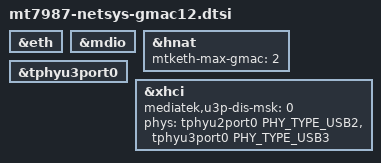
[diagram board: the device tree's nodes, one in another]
// SPDX-License-Identifier: (GPL-2.0 OR MIT)

#include "mt7987-netsys-gmac123.dtsi"

&eth {
	/delete-node/ mac@2;
};

&mdio {
	/delete-node/ phy@11;
};

&hnat {
	mtketh-max-gmac = <2>;
};

&tphyu3port0 {
	status = "okay";
};

&xhci {
	mediatek,u3p-dis-msk=<0>;

	phys = <&tphyu2port0 PHY_TYPE_USB2>,
	       <&tphyu3port0 PHY_TYPE_USB3>;
};
